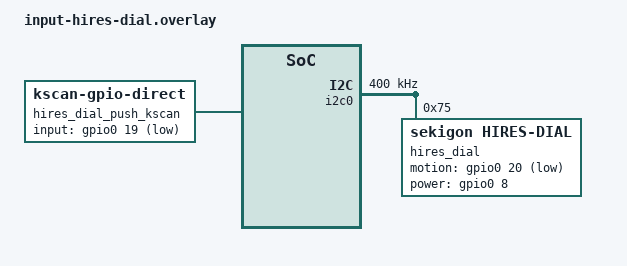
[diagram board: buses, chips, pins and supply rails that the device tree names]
#include <zephyr/dt-bindings/gpio/gpio.h>
#include <zephyr/dt-bindings/gpio/nordic-nrf-gpio.h>
#include <zephyr/dt-bindings/i2c/i2c.h>

/ {
    hires_dial_push_kscan: hires_dial_push_kscan {
        compatible = "zmk,kscan-gpio-direct";

        input-gpios =
            <&gpio0 19 (GPIO_ACTIVE_LOW | GPIO_PULL_UP)>;

        debounce-press-ms = <5>;
        debounce-release-ms = <5>;
    };
};

&i2c0 {
    status = "okay";
    compatible = "nordic,nrf-twim";
    pinctrl-0 = <&i2c0_default>;
    pinctrl-1 = <&i2c0_sleep>;
    pinctrl-names = "default", "sleep";
    clock-frequency = <I2C_BITRATE_FAST>;

    hires_dial: hires_dial@75 {
        status = "okay";
        compatible = "sekigon,hires-dial";
        reg = <0x75>;

        res-cpi = <1275>;
        counts-per-revolution = <1275>;
        motion-read-interval-ms = <8>;

        motion-gpios =
            <&gpio0 20 (GPIO_ACTIVE_LOW | GPIO_PULL_UP)>;
        power-gpios =
            <&gpio0 8 (GPIO_ACTIVE_HIGH | NRF_GPIO_DRIVE_H1)>;

        sleep1-enable;
        sleep2-enable;
    };
};
